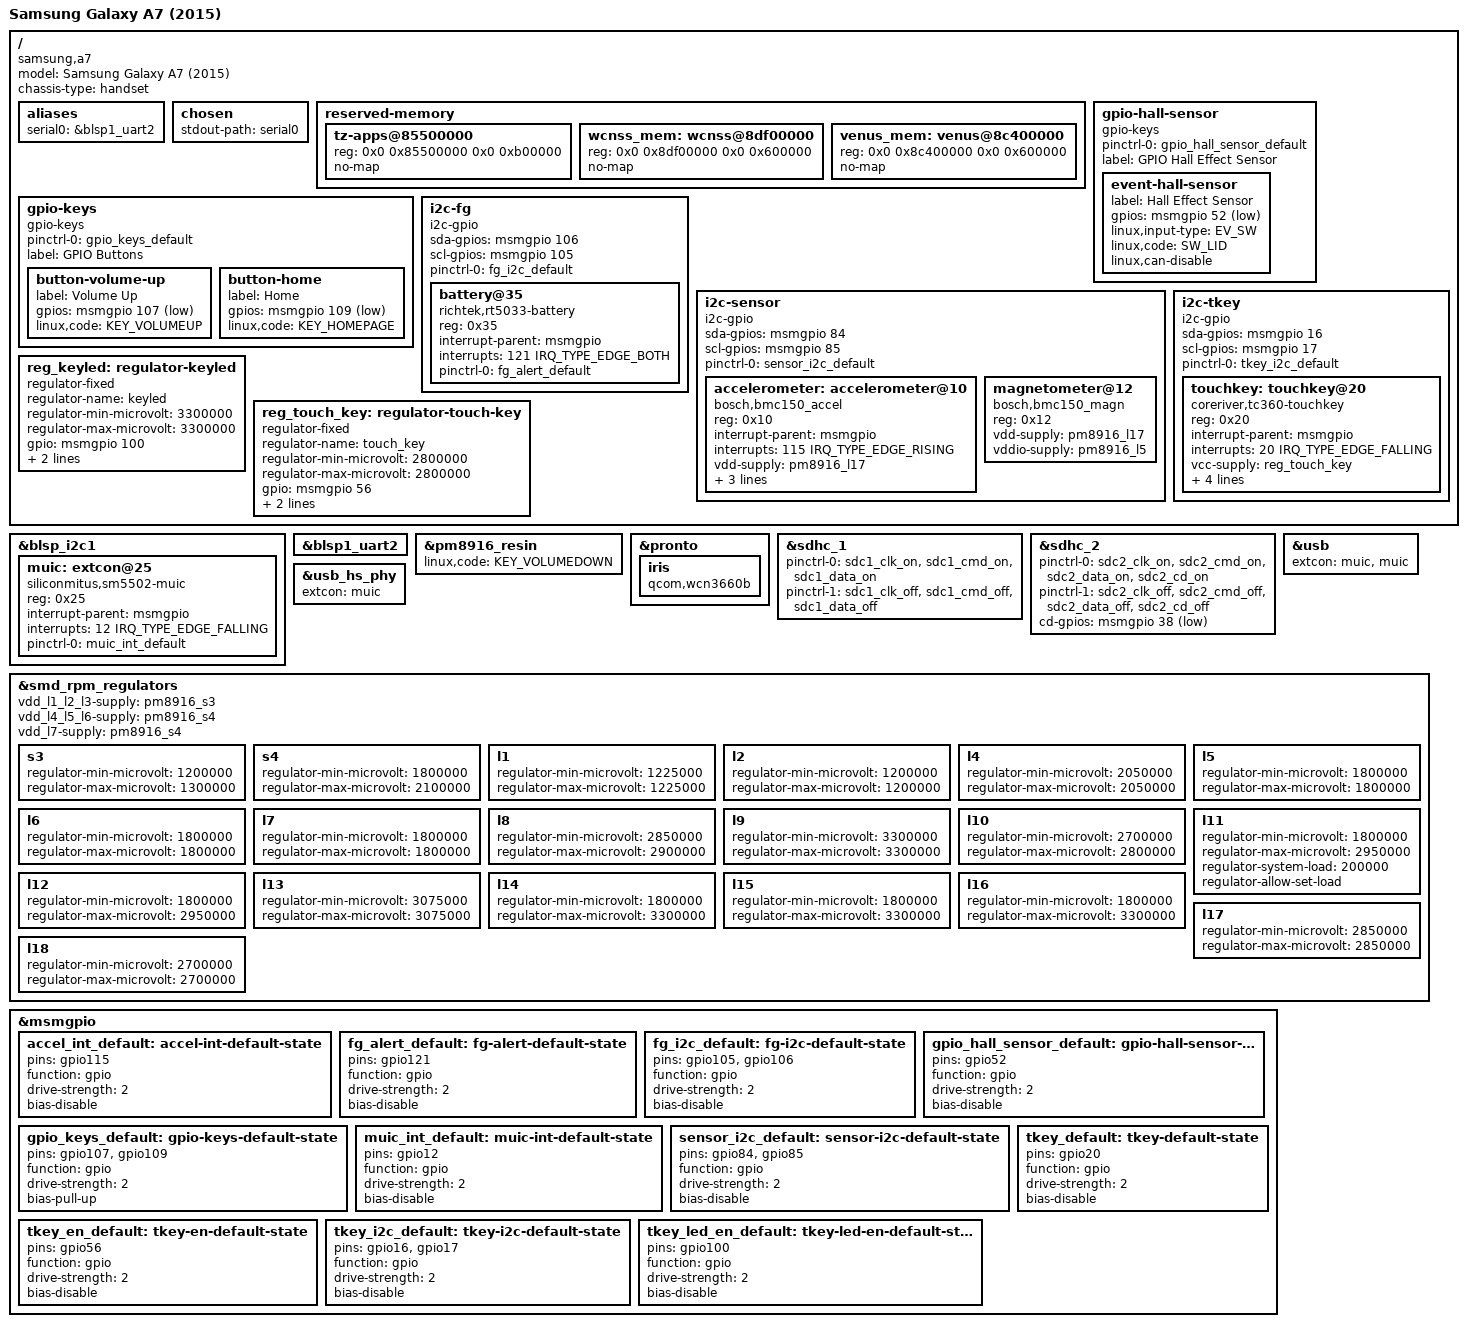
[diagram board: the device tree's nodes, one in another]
// SPDX-License-Identifier: GPL-2.0-only

/dts-v1/;

#include "msm8939-pm8916.dtsi"

#include <dt-bindings/gpio/gpio.h>
#include <dt-bindings/input/input.h>
#include <dt-bindings/interrupt-controller/irq.h>

/ {
	model = "Samsung Galaxy A7 (2015)";
	compatible = "samsung,a7", "qcom,msm8939";
	chassis-type = "handset";

	aliases {
		serial0 = &blsp1_uart2;
	};

	chosen {
		stdout-path = "serial0";
	};

	reserved-memory {
		/* Additional memory used by Samsung firmware modifications */
		tz-apps@85500000 {
			reg = <0x0 0x85500000 0x0 0xb00000>;
			no-map;
		};

		/delete-node/ wcnss@8bd00000;
		wcnss_mem: wcnss@8df00000 {
			reg = <0x0 0x8df00000 0x0 0x600000>;
			no-map;
		};

		/delete-node/ venus@8c300000;
		venus_mem: venus@8c400000 {
			reg = <0x0 0x8c400000 0x0 0x600000>;
			no-map;
		};
	};

	gpio-hall-sensor {
		compatible = "gpio-keys";

		pinctrl-0 = <&gpio_hall_sensor_default>;
		pinctrl-names = "default";

		label = "GPIO Hall Effect Sensor";

		event-hall-sensor {
			label = "Hall Effect Sensor";
			gpios = <&msmgpio 52 GPIO_ACTIVE_LOW>;
			linux,input-type = <EV_SW>;
			linux,code = <SW_LID>;
			linux,can-disable;
		};
	};

	gpio-keys {
		compatible = "gpio-keys";

		pinctrl-0 = <&gpio_keys_default>;
		pinctrl-names = "default";

		label = "GPIO Buttons";

		button-volume-up {
			label = "Volume Up";
			gpios = <&msmgpio 107 GPIO_ACTIVE_LOW>;
			linux,code = <KEY_VOLUMEUP>;
		};

		button-home {
			label = "Home";
			gpios = <&msmgpio 109 GPIO_ACTIVE_LOW>;
			linux,code = <KEY_HOMEPAGE>;
		};
	};

	i2c-fg {
		compatible = "i2c-gpio";
		sda-gpios = <&msmgpio 106 (GPIO_ACTIVE_HIGH|GPIO_OPEN_DRAIN)>;
		scl-gpios = <&msmgpio 105 (GPIO_ACTIVE_HIGH|GPIO_OPEN_DRAIN)>;

		pinctrl-0 = <&fg_i2c_default>;
		pinctrl-names = "default";

		#address-cells = <1>;
		#size-cells = <0>;

		battery@35 {
			compatible = "richtek,rt5033-battery";
			reg = <0x35>;

			interrupt-parent = <&msmgpio>;
			interrupts = <121 IRQ_TYPE_EDGE_BOTH>;

			pinctrl-0 = <&fg_alert_default>;
			pinctrl-names = "default";
		};
	};

	i2c-sensor {
		compatible = "i2c-gpio";
		sda-gpios = <&msmgpio 84 (GPIO_ACTIVE_HIGH|GPIO_OPEN_DRAIN)>;
		scl-gpios = <&msmgpio 85 (GPIO_ACTIVE_HIGH|GPIO_OPEN_DRAIN)>;

		pinctrl-0 = <&sensor_i2c_default>;
		pinctrl-names = "default";

		#address-cells = <1>;
		#size-cells = <0>;

		accelerometer: accelerometer@10 {
			compatible = "bosch,bmc150_accel";
			reg = <0x10>;
			interrupt-parent = <&msmgpio>;
			interrupts = <115 IRQ_TYPE_EDGE_RISING>;

			vdd-supply = <&pm8916_l17>;
			vddio-supply = <&pm8916_l5>;

			pinctrl-0 = <&accel_int_default>;
			pinctrl-names = "default";

			mount-matrix = "-1", "0", "0",
					"0", "-1", "0",
					"0", "0", "1";
		};

		magnetometer@12 {
			compatible = "bosch,bmc150_magn";
			reg = <0x12>;

			vdd-supply = <&pm8916_l17>;
			vddio-supply = <&pm8916_l5>;
		};
	};

	i2c-tkey {
		compatible = "i2c-gpio";
		sda-gpios = <&msmgpio 16 (GPIO_ACTIVE_HIGH|GPIO_OPEN_DRAIN)>;
		scl-gpios = <&msmgpio 17 (GPIO_ACTIVE_HIGH|GPIO_OPEN_DRAIN)>;

		pinctrl-0 = <&tkey_i2c_default>;
		pinctrl-names = "default";

		#address-cells = <1>;
		#size-cells = <0>;

		touchkey: touchkey@20 {
			/* Note: Actually an ABOV MCU that implements same interface */
			compatible = "coreriver,tc360-touchkey";
			reg = <0x20>;

			interrupt-parent = <&msmgpio>;
			interrupts = <20 IRQ_TYPE_EDGE_FALLING>;

			vcc-supply = <&reg_touch_key>;
			vdd-supply = <&reg_keyled>;
			vddio-supply = <&pm8916_l6>;

			linux,keycodes = <KEY_APPSELECT KEY_BACK>;

			pinctrl-0 = <&tkey_default>;
			pinctrl-names = "default";
		};
	};

	reg_keyled: regulator-keyled {
		compatible = "regulator-fixed";
		regulator-name = "keyled";
		regulator-min-microvolt = <3300000>;
		regulator-max-microvolt = <3300000>;

		/* NOTE: On some variants e.g. SM-A700FD it's GPIO 91 */
		gpio = <&msmgpio 100 GPIO_ACTIVE_HIGH>;
		enable-active-high;

		pinctrl-0 = <&tkey_led_en_default>;
		pinctrl-names = "default";
	};

	reg_touch_key: regulator-touch-key {
		compatible = "regulator-fixed";
		regulator-name = "touch_key";
		regulator-min-microvolt = <2800000>;
		regulator-max-microvolt = <2800000>;

		gpio = <&msmgpio 56 GPIO_ACTIVE_HIGH>;
		enable-active-high;

		pinctrl-0 = <&tkey_en_default>;
		pinctrl-names = "default";
	};
};

&blsp_i2c1 {
	status = "okay";

	muic: extcon@25 {
		compatible = "siliconmitus,sm5502-muic";
		reg = <0x25>;

		interrupt-parent = <&msmgpio>;
		interrupts = <12 IRQ_TYPE_EDGE_FALLING>;

		pinctrl-0 = <&muic_int_default>;
		pinctrl-names = "default";
	};
};

&blsp1_uart2 {
	status = "okay";
};

&pm8916_resin {
	linux,code = <KEY_VOLUMEDOWN>;
	status = "okay";
};

&pronto {
	status = "okay";

	iris {
		compatible = "qcom,wcn3660b";
	};
};

&sdhc_1 {
	pinctrl-0 = <&sdc1_clk_on &sdc1_cmd_on &sdc1_data_on>;
	pinctrl-1 = <&sdc1_clk_off &sdc1_cmd_off &sdc1_data_off>;
	pinctrl-names = "default", "sleep";

	status = "okay";
};

&sdhc_2 {
	pinctrl-0 = <&sdc2_clk_on &sdc2_cmd_on &sdc2_data_on &sdc2_cd_on>;
	pinctrl-1 = <&sdc2_clk_off &sdc2_cmd_off &sdc2_data_off &sdc2_cd_off>;
	pinctrl-names = "default", "sleep";

	cd-gpios = <&msmgpio 38 GPIO_ACTIVE_LOW>;

	status = "okay";
};

&usb {
	extcon = <&muic>, <&muic>;
	status = "okay";
};

&usb_hs_phy {
	extcon = <&muic>;
};

&smd_rpm_regulators {
	vdd_l1_l2_l3-supply = <&pm8916_s3>;
	vdd_l4_l5_l6-supply = <&pm8916_s4>;
	vdd_l7-supply = <&pm8916_s4>;

	s3 {
		regulator-min-microvolt = <1200000>;
		regulator-max-microvolt = <1300000>;
	};

	s4 {
		regulator-min-microvolt = <1800000>;
		regulator-max-microvolt = <2100000>;
	};

	l1 {
		regulator-min-microvolt = <1225000>;
		regulator-max-microvolt = <1225000>;
	};

	l2 {
		regulator-min-microvolt = <1200000>;
		regulator-max-microvolt = <1200000>;
	};

	l4 {
		regulator-min-microvolt = <2050000>;
		regulator-max-microvolt = <2050000>;
	};

	l5 {
		regulator-min-microvolt = <1800000>;
		regulator-max-microvolt = <1800000>;
	};

	l6 {
		regulator-min-microvolt = <1800000>;
		regulator-max-microvolt = <1800000>;
	};

	l7 {
		regulator-min-microvolt = <1800000>;
		regulator-max-microvolt = <1800000>;
	};

	l8 {
		regulator-min-microvolt = <2850000>;
		regulator-max-microvolt = <2900000>;
	};

	l9 {
		regulator-min-microvolt = <3300000>;
		regulator-max-microvolt = <3300000>;
	};

	l10 {
		regulator-min-microvolt = <2700000>;
		regulator-max-microvolt = <2800000>;
	};

	l11 {
		regulator-min-microvolt = <1800000>;
		regulator-max-microvolt = <2950000>;
		regulator-system-load = <200000>;
		regulator-allow-set-load;
	};

	l12 {
		regulator-min-microvolt = <1800000>;
		regulator-max-microvolt = <2950000>;
	};

	l13 {
		regulator-min-microvolt = <3075000>;
		regulator-max-microvolt = <3075000>;
	};

	l14 {
		regulator-min-microvolt = <1800000>;
		regulator-max-microvolt = <3300000>;
	};

	l15 {
		regulator-min-microvolt = <1800000>;
		regulator-max-microvolt = <3300000>;
	};

	l16 {
		regulator-min-microvolt = <1800000>;
		regulator-max-microvolt = <3300000>;
	};

	l17 {
		regulator-min-microvolt = <2850000>;
		regulator-max-microvolt = <2850000>;
	};

	l18 {
		regulator-min-microvolt = <2700000>;
		regulator-max-microvolt = <2700000>;
	};
};

&msmgpio {
	accel_int_default: accel-int-default-state {
		pins = "gpio115";
		function = "gpio";
		drive-strength = <2>;
		bias-disable;
	};

	fg_alert_default: fg-alert-default-state {
		pins = "gpio121";
		function = "gpio";
		drive-strength = <2>;
		bias-disable;
	};

	fg_i2c_default: fg-i2c-default-state {
		pins = "gpio105", "gpio106";
		function = "gpio";
		drive-strength = <2>;
		bias-disable;
	};

	gpio_hall_sensor_default: gpio-hall-sensor-default-state {
		pins = "gpio52";
		function = "gpio";
		drive-strength = <2>;
		bias-disable;
	};

	gpio_keys_default: gpio-keys-default-state {
		pins = "gpio107", "gpio109";
		function = "gpio";
		drive-strength = <2>;
		bias-pull-up;
	};

	muic_int_default: muic-int-default-state {
		pins = "gpio12";
		function = "gpio";
		drive-strength = <2>;
		bias-disable;
	};

	sensor_i2c_default: sensor-i2c-default-state {
		pins = "gpio84", "gpio85";
		function = "gpio";
		drive-strength = <2>;
		bias-disable;
	};

	tkey_default: tkey-default-state {
		pins = "gpio20";
		function = "gpio";
		drive-strength = <2>;
		bias-disable;
	};

	tkey_en_default: tkey-en-default-state {
		pins = "gpio56";
		function = "gpio";
		drive-strength = <2>;
		bias-disable;
	};

	tkey_i2c_default: tkey-i2c-default-state {
		pins = "gpio16", "gpio17";
		function = "gpio";
		drive-strength = <2>;
		bias-disable;
	};

	tkey_led_en_default: tkey-led-en-default-state {
		pins = "gpio100";
		function = "gpio";
		drive-strength = <2>;
		bias-disable;
	};
};
